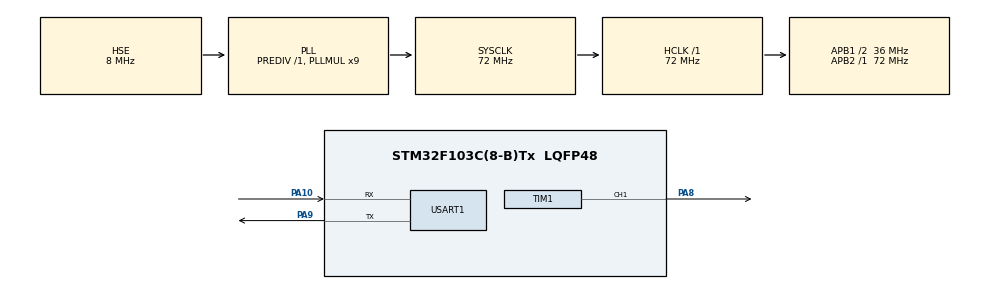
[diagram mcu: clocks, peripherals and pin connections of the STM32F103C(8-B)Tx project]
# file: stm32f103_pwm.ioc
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Dma.Request0=TIM1_UP
Dma.TIM1_UP.0.Direction=DMA_MEMORY_TO_PERIPH
Dma.TIM1_UP.0.Instance=DMA1_Channel5
Dma.TIM1_UP.0.MemDataAlignment=DMA_MDATAALIGN_HALFWORD
Dma.TIM1_UP.0.MemInc=DMA_MINC_ENABLE
Dma.TIM1_UP.0.Mode=DMA_CIRCULAR
Dma.TIM1_UP.0.PeriphDataAlignment=DMA_PDATAALIGN_HALFWORD
Dma.TIM1_UP.0.PeriphInc=DMA_PINC_DISABLE
Dma.TIM1_UP.0.Priority=DMA_PRIORITY_HIGH
FREERTOS.Tasks01=defaultTask,24,128,StartDefaultTask,Default,NULL,Dynamic,NULL,NULL;controle_task,24,128,StartTask02,Default,NULL,Dynamic,NULL,NULL
FREERTOS.configUSE_NEWLIB_REENTRANT=1
Mcu.Family=STM32F1
Mcu.Name=STM32F103C(8-B)Tx
Mcu.Package=LQFP48
NVIC.DMA1_Channel5_IRQn=true\:5\:0\:false\:false\:true\:true\:false\:true\:true
NVIC.PriorityGroup=NVIC_PRIORITYGROUP_4
NVIC.TIM2_IRQn=true\:15\:0\:false\:false\:true\:false\:false\:true\:true
NVIC.TimeBase=TIM2_IRQn
NVIC.TimeBaseIP=TIM2
PA10.Mode=Asynchronous
PA10.Signal=USART1_RX
PA13.Mode=Serial_Wire
PA13.Signal=SYS_JTMS-SWDIO
PA14.Mode=Serial_Wire
PA14.Signal=SYS_JTCK-SWCLK
PA8.Signal=S_TIM1_CH1
PA9.Mode=Asynchronous
PA9.Signal=USART1_TX
PD0-OSC_IN.Mode=HSE-External-Oscillator
PD0-OSC_IN.Signal=RCC_OSC_IN
PD1-OSC_OUT.Mode=HSE-External-Oscillator
PD1-OSC_OUT.Signal=RCC_OSC_OUT
ProjectManager.HeapSize=0x200
ProjectManager.StackSize=0x400
ProjectManager.TargetToolchain=STM32CubeIDE
RCC.AHBFreq_Value=72000000
RCC.APB1CLKDivider=RCC_HCLK_DIV2
RCC.APB1Freq_Value=36000000
RCC.APB1TimFreq_Value=72000000
RCC.APB2Freq_Value=72000000
RCC.APB2TimFreq_Value=72000000
RCC.HCLKFreq_Value=72000000
RCC.PLLMUL=RCC_PLL_MUL9
RCC.PLLSourceVirtual=RCC_PLLSOURCE_HSE
RCC.SYSCLKFreq_VALUE=72000000
RCC.SYSCLKSource=RCC_SYSCLKSOURCE_PLLCLK
RCC.USBFreq_Value=72000000
SH.S_TIM1_CH1.0=TIM1_CH1,PWM Generation1 CH1
TIM1.AutoReloadPreload=TIM_AUTORELOAD_PRELOAD_ENABLE
TIM1.Channel-PWM\ Generation1\ CH1=TIM_CHANNEL_1
TIM1.CounterMode=TIM_COUNTERMODE_CENTERALIGNED1
TIM1.Period=7199
TIM1.Pulse-PWM\ Generation1\ CH1=3600
USART1.VirtualMode=VM_ASYNC
VP_FREERTOS_VS_CMSIS_V2.Mode=CMSIS_V2
VP_SYS_VS_tim2.Mode=TIM2
VP_TIM1_VS_ClockSourceINT.Mode=Internal
board=custom

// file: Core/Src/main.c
/* USER CODE BEGIN Header */
/**
 ******************************************************************************
 * @file           : main.c
 * @brief          : Main program body
 ******************************************************************************
 */
/* USER CODE END Header */
#include "main.h"
#include "cmsis_os.h"

/* USER CODE BEGIN Includes */
#include "math.h"
#include "string.h"
#include "stdio.h"
#include "stdlib.h"
/* USER CODE END Includes */

/* USER CODE BEGIN PD */

#define PWM_SAMPLES    64
#define PWM_PERIOD     7199

/* USER CODE END PD */

/* USER CODE BEGIN PM */

uint32_t pwmBuffer[PWM_SAMPLES];

uint8_t rxByte;
char rxBuffer[20];
uint8_t rxIndex = 0;

volatile uint16_t modulationIndex = 100;

/* USER CODE END PM */

TIM_HandleTypeDef htim1;
DMA_HandleTypeDef hdma_tim1_up;

UART_HandleTypeDef huart1;

/* Definitions for defaultTask */
osThreadId_t defaultTaskHandle;
const osThreadAttr_t defaultTask_attributes = {
  .name = "defaultTask",
  .stack_size = 128 * 4,
  .priority = (osPriority_t) osPriorityNormal,
};
/* Definitions for controle_task */
osThreadId_t controle_taskHandle;
const osThreadAttr_t controle_task_attributes = {
  .name = "controle_task",
  .stack_size = 128 * 4,
  .priority = (osPriority_t) osPriorityNormal,
};

void SystemClock_Config(void);
static void MX_GPIO_Init(void);
static void MX_DMA_Init(void);
static void MX_TIM1_Init(void);
static void MX_USART1_UART_Init(void);
void StartDefaultTask(void *argument);
void StartTask02(void *argument);

/* USER CODE BEGIN 0 */

void Generate_PWM_Buffer(uint16_t amplitude) {
	for (int i = 0; i < PWM_SAMPLES; i++) {
		float angle;

		angle = (2.0f * 3.14159265f * i) / PWM_SAMPLES;

		float sineValue;

		sineValue = (sinf(angle) + 1.0f) / 2.0f;

		pwmBuffer[i] = (uint16_t) (sineValue * amplitude);
	}
}

/* USER CODE END 0 */

int main(void)
{

  /* MCU Configuration--------------------------------------------------------*/

  /* Reset of all peripherals, Initializes the Flash interface and the Systick. */
  HAL_Init();

  /* Configure the system clock */
  SystemClock_Config();

  /* Initialize all configured peripherals */
  MX_GPIO_Init();
  MX_DMA_Init();
  MX_TIM1_Init();
  MX_USART1_UART_Init();
  /* USER CODE BEGIN 2 */

  /* UART RX */
  HAL_UART_Receive_IT(&huart1, &rxByte, 1);

  /* Create sine lookup table */
  Generate_PWM_Buffer(PWM_PERIOD);

  /* Start PWM output */
  HAL_TIM_PWM_Start(&htim1, TIM_CHANNEL_1);

  /* Enable TIM1 main output */
  __HAL_TIM_MOE_ENABLE(&htim1);

  /* Enable TIM1 Update DMA request */
  __HAL_TIM_ENABLE_DMA(&htim1, TIM_DMA_UPDATE);

  /* Start DMA:
     Source      = pwmBuffer[]
     Destination = TIM1->CCR1
     Length      = PWM_SAMPLES
  */
  HAL_DMA_Start(
          &hdma_tim1_up,
          (uint32_t)pwmBuffer,
          (uint32_t)&TIM1->CCR1,
          PWM_SAMPLES);

  /* Enable DMA channel */
  __HAL_DMA_ENABLE(&hdma_tim1_up);

  /* Start timer counter */
  __HAL_TIM_ENABLE(&htim1);

//  volatile uint16_t test_ccr;
//  volatile uint16_t test_cnt;
//  volatile uint16_t test_cndtr;
//
//  while (1)
//  {
//      test_ccr   = TIM1->CCR1;
//      test_cnt   = TIM1->CNT;
//      test_cndtr = DMA1_Channel5->CNDTR;
//
//      HAL_Delay(100);
//  }
  /* USER CODE END 2 */

  /* Init scheduler */
  osKernelInitialize();

  /* Create the thread(s) */
  /* creation of defaultTask */
  defaultTaskHandle = osThreadNew(StartDefaultTask, NULL, &defaultTask_attributes);

  /* creation of controle_task */
  controle_taskHandle = osThreadNew(StartTask02, NULL, &controle_task_attributes);

  /* Start scheduler */
  osKernelStart();

  /* We should never get here as control is now taken by the scheduler */

  /* Infinite loop */
  while (1)
  {

  }
}

void SystemClock_Config(void)
{
  RCC_OscInitTypeDef RCC_OscInitStruct = {0};
  RCC_ClkInitTypeDef RCC_ClkInitStruct = {0};

  /** Initializes the RCC Oscillators according to the specified parameters
  * in the RCC_OscInitTypeDef structure.
  */
  RCC_OscInitStruct.OscillatorType = RCC_OSCILLATORTYPE_HSE;
  RCC_OscInitStruct.HSEState = RCC_HSE_ON;
  RCC_OscInitStruct.HSEPredivValue = RCC_HSE_PREDIV_DIV1;
  RCC_OscInitStruct.HSIState = RCC_HSI_ON;
  RCC_OscInitStruct.PLL.PLLState = RCC_PLL_ON;
  RCC_OscInitStruct.PLL.PLLSource = RCC_PLLSOURCE_HSE;
  RCC_OscInitStruct.PLL.PLLMUL = RCC_PLL_MUL9;
  if (HAL_RCC_OscConfig(&RCC_OscInitStruct) != HAL_OK)
  {
    Error_Handler();
  }

  /** Initializes the CPU, AHB and APB buses clocks
  */
  RCC_ClkInitStruct.ClockType = RCC_CLOCKTYPE_HCLK|RCC_CLOCKTYPE_SYSCLK
                              |RCC_CLOCKTYPE_PCLK1|RCC_CLOCKTYPE_PCLK2;
  RCC_ClkInitStruct.SYSCLKSource = RCC_SYSCLKSOURCE_PLLCLK;
  RCC_ClkInitStruct.AHBCLKDivider = RCC_SYSCLK_DIV1;
  RCC_ClkInitStruct.APB1CLKDivider = RCC_HCLK_DIV2;
  RCC_ClkInitStruct.APB2CLKDivider = RCC_HCLK_DIV1;

  if (HAL_RCC_ClockConfig(&RCC_ClkInitStruct, FLASH_LATENCY_2) != HAL_OK)
  {
    Error_Handler();
  }
}

static void MX_TIM1_Init(void)
{

  TIM_ClockConfigTypeDef sClockSourceConfig = {0};
  TIM_MasterConfigTypeDef sMasterConfig = {0};
  TIM_OC_InitTypeDef sConfigOC = {0};
  TIM_BreakDeadTimeConfigTypeDef sBreakDeadTimeConfig = {0};

  htim1.Instance = TIM1;
  htim1.Init.Prescaler = 0;
  htim1.Init.CounterMode = TIM_COUNTERMODE_CENTERALIGNED1;
  htim1.Init.Period = 7199;
  htim1.Init.ClockDivision = TIM_CLOCKDIVISION_DIV1;
  htim1.Init.RepetitionCounter = 0;
  htim1.Init.AutoReloadPreload = TIM_AUTORELOAD_PRELOAD_ENABLE;
  if (HAL_TIM_Base_Init(&htim1) != HAL_OK)
  {
    Error_Handler();
  }
  sClockSourceConfig.ClockSource = TIM_CLOCKSOURCE_INTERNAL;
  if (HAL_TIM_ConfigClockSource(&htim1, &sClockSourceConfig) != HAL_OK)
  {
    Error_Handler();
  }
  if (HAL_TIM_PWM_Init(&htim1) != HAL_OK)
  {
    Error_Handler();
  }
  sMasterConfig.MasterOutputTrigger = TIM_TRGO_RESET;
  sMasterConfig.MasterSlaveMode = TIM_MASTERSLAVEMODE_DISABLE;
  if (HAL_TIMEx_MasterConfigSynchronization(&htim1, &sMasterConfig) != HAL_OK)
  {
    Error_Handler();
  }
  sConfigOC.OCMode = TIM_OCMODE_PWM1;
  sConfigOC.Pulse = 3600;
  sConfigOC.OCPolarity = TIM_OCPOLARITY_HIGH;
  sConfigOC.OCNPolarity = TIM_OCNPOLARITY_HIGH;
  sConfigOC.OCFastMode = TIM_OCFAST_DISABLE;
  sConfigOC.OCIdleState = TIM_OCIDLESTATE_RESET;
  sConfigOC.OCNIdleState = TIM_OCNIDLESTATE_RESET;
  if (HAL_TIM_PWM_ConfigChannel(&htim1, &sConfigOC, TIM_CHANNEL_1) != HAL_OK)
  {
    Error_Handler();
  }
  sBreakDeadTimeConfig.OffStateRunMode = TIM_OSSR_DISABLE;
  sBreakDeadTimeConfig.OffStateIDLEMode = TIM_OSSI_DISABLE;
  sBreakDeadTimeConfig.LockLevel = TIM_LOCKLEVEL_OFF;
  sBreakDeadTimeConfig.DeadTime = 0;
  sBreakDeadTimeConfig.BreakState = TIM_BREAK_DISABLE;
  sBreakDeadTimeConfig.BreakPolarity = TIM_BREAKPOLARITY_HIGH;
  sBreakDeadTimeConfig.AutomaticOutput = TIM_AUTOMATICOUTPUT_DISABLE;
  if (HAL_TIMEx_ConfigBreakDeadTime(&htim1, &sBreakDeadTimeConfig) != HAL_OK)
  {
    Error_Handler();
  }
  HAL_TIM_MspPostInit(&htim1);

}

static void MX_USART1_UART_Init(void)
{

  huart1.Instance = USART1;
  huart1.Init.BaudRate = 115200;
  huart1.Init.WordLength = UART_WORDLENGTH_8B;
  huart1.Init.StopBits = UART_STOPBITS_1;
  huart1.Init.Parity = UART_PARITY_NONE;
  huart1.Init.Mode = UART_MODE_TX_RX;
  huart1.Init.HwFlowCtl = UART_HWCONTROL_NONE;
  huart1.Init.OverSampling = UART_OVERSAMPLING_16;
  if (HAL_UART_Init(&huart1) != HAL_OK)
  {
    Error_Handler();
  }

}

static void MX_DMA_Init(void)
{

  /* DMA controller clock enable */
  __HAL_RCC_DMA1_CLK_ENABLE();

  /* DMA interrupt init */
  /* DMA1_Channel5_IRQn interrupt configuration */
  HAL_NVIC_SetPriority(DMA1_Channel5_IRQn, 5, 0);
  HAL_NVIC_EnableIRQ(DMA1_Channel5_IRQn);

}

static void MX_GPIO_Init(void)
{

  /* GPIO Ports Clock Enable */
  __HAL_RCC_GPIOD_CLK_ENABLE();
  __HAL_RCC_GPIOA_CLK_ENABLE();

}

/* USER CODE BEGIN 4 */

void HAL_UART_RxCpltCallback(UART_HandleTypeDef *huart) {
	if (huart->Instance == USART1) {
		if (rxByte != '\n' && rxIndex < sizeof(rxBuffer) - 1) {
			rxBuffer[rxIndex++] = rxByte;
		} else {
			rxBuffer[rxIndex] = '\0';

			if (rxBuffer[0] == 'F') {
				int percent;

				percent = atoi(&rxBuffer[1]);

				if (percent >= 10 && percent <= 100) {
					modulationIndex = percent;

					Generate_PWM_Buffer((PWM_PERIOD * modulationIndex) / 100);
				}
			}

			rxIndex = 0;

			memset(rxBuffer, 0, sizeof(rxBuffer));
		}

		HAL_UART_Receive_IT(&huart1, &rxByte, 1);
	}
}

/* USER CODE END 4 */

/* USER CODE BEGIN Header_StartDefaultTask */

void StartDefaultTask(void *argument) {
	for (;;) {
		osDelay(1);
	}
}

/* USER CODE END Header_StartDefaultTask */

/* USER CODE BEGIN Header_StartTask02 */

void StartTask02(void *argument) {
	for (;;) {
		osDelay(1);
	}
}

/* USER CODE END Header_StartTask02 */

void HAL_TIM_PeriodElapsedCallback(TIM_HandleTypeDef *htim)
{
  if (htim->Instance == TIM2)
  {
    HAL_IncTick();
  }
}

void Error_Handler(void)
{
  __disable_irq();
  while (1)
  {
  }
}
